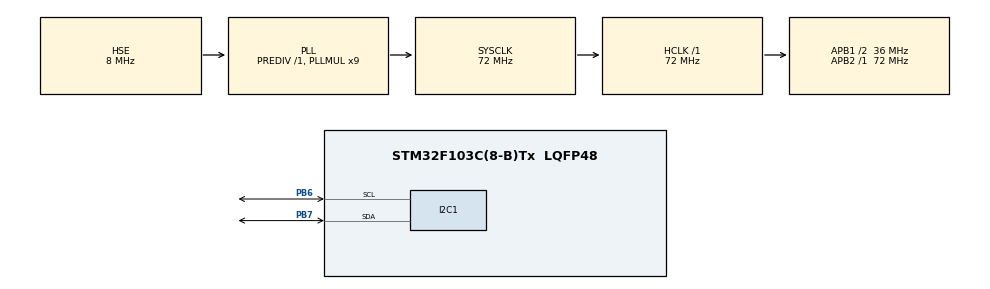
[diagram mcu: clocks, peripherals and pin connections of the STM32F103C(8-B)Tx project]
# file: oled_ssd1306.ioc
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I2C1.I2C_Mode=I2C_Fast
Mcu.Family=STM32F1
Mcu.Name=STM32F103C(8-B)Tx
Mcu.Package=LQFP48
NVIC.PriorityGroup=NVIC_PRIORITYGROUP_4
PA13.Mode=Serial_Wire
PA13.Signal=SYS_JTMS-SWDIO
PA14.Mode=Serial_Wire
PA14.Signal=SYS_JTCK-SWCLK
PB6.Mode=I2C
PB6.Signal=I2C1_SCL
PB7.Mode=I2C
PB7.Signal=I2C1_SDA
PD0-OSC_IN.Mode=HSE-External-Oscillator
PD0-OSC_IN.Signal=RCC_OSC_IN
PD1-OSC_OUT.Mode=HSE-External-Oscillator
PD1-OSC_OUT.Signal=RCC_OSC_OUT
ProjectManager.HeapSize=0x200
ProjectManager.StackSize=0x400
ProjectManager.TargetToolchain=STM32CubeIDE
RCC.AHBFreq_Value=72000000
RCC.APB1CLKDivider=RCC_HCLK_DIV2
RCC.APB1Freq_Value=36000000
RCC.APB1TimFreq_Value=72000000
RCC.APB2Freq_Value=72000000
RCC.APB2TimFreq_Value=72000000
RCC.HCLKFreq_Value=72000000
RCC.PLLMUL=RCC_PLL_MUL9
RCC.PLLSourceVirtual=RCC_PLLSOURCE_HSE
RCC.SYSCLKFreq_VALUE=72000000
RCC.SYSCLKSource=RCC_SYSCLKSOURCE_PLLCLK
RCC.USBFreq_Value=72000000
board=custom

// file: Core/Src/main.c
/* USER CODE BEGIN Header */
/**
  ******************************************************************************
  * @file           : main.c
  * @brief          : Main program body
  ******************************************************************************
  * @attention
  *
  * <h2><center>&copy; Copyright (c) 2021 STMicroelectronics.
  * All rights reserved.</center></h2>
  *
  * This software component is licensed by ST under BSD 3-Clause license,
  * the "License"; You may not use this file except in compliance with the
  * License. You may obtain a copy of the License at:
  *                        opensource.org/licenses/BSD-3-Clause
  *
  ******************************************************************************
  */
/* USER CODE END Header */
#include "main.h"
/* USER CODE BEGIN Includes */
#include "fonts.h"
#include "ssd1306.h"
#include "test.h"
#include "bitmap.h"
/* USER CODE END Includes */

I2C_HandleTypeDef hi2c1;

void SystemClock_Config(void);
static void MX_GPIO_Init(void);
static void MX_I2C1_Init(void);

/* USER CODE BEGIN 0 */

// FUNCION UTIL PARA CONTAR LA CANTIDAD DE DIGITOS DE UN NUMERO
int count_digits(int number)
{
	int digits = 0;
	while(number)
	{
		number /= 10;
		digits++;
	}
	return digits;
}

// IMPRIME EL ICONO DE BATERIA (VALORES DE 0 A 4, 4=LLENA, 0=VACIA)
void printoled_battery(int state)
{
	SSD1306_DrawBitmap(95, 0, battery_icon_4, 32, 18, 0); //LIMPIO LA ZONA
	SSD1306_UpdateScreen();
	switch(state){
	case 0:
		SSD1306_DrawBitmap(95, 0, battery_icon_0, 32, 18, 1); //ORIGINAL
		break;
	case 1:
		SSD1306_DrawBitmap(95, 0, battery_icon_1, 32, 18, 1); //ORIGINAL
		break;
	case 2:
		SSD1306_DrawBitmap(95, 0, battery_icon_2, 32, 18, 1); //ORIGINAL
		break;
	case 3:
		SSD1306_DrawBitmap(95, 0, battery_icon_3, 32, 18, 1); //ORIGINAL
		break;
	case 4:
		SSD1306_DrawBitmap(95, 0, battery_icon_4, 32, 18, 1); //ORIGINAL
		break;
	default:
		state = 0;
	}
	SSD1306_UpdateScreen();
}

// IMPRIME EL MENU
void printoled_menu()
{
	SSD1306_GotoXY(0,0);
	SSD1306_Puts("MENU", &Font_7x10, 1);
	SSD1306_GotoXY(0,10);
	SSD1306_Puts("1- Pesar", &Font_7x10, 1);
	SSD1306_GotoXY(0,20);
	SSD1306_Puts("2- Calibrar", &Font_7x10, 1);
	SSD1306_GotoXY(0,30);
	SSD1306_Puts("3- Tarar", &Font_7x10, 1);
	SSD1306_GotoXY(0,40);
	SSD1306_Puts("4- Calcular Precio", &Font_7x10, 1);
	SSD1306_GotoXY(0,50);
	SSD1306_Puts("5- Conectar a PC", &Font_7x10, 1);
	SSD1306_UpdateScreen();
}

//RECIBE UN VALOR INT DE PESO(EN GRAMOS) Y LO IMPRIME EN PANTALLA INCLUYENDO 'g' SI UNIT=0 o 'kg' SI UNIT=1 Y WEIGHT ES MAYOR A 1000
//EN CASO DE UNIT=1 SOLO IMRPIME NUMEROS DE HASTA 9,999 KG (PARA ESTA BALANZA ES SUFICIENTE)
void printoled_weight(int weight,int unit)
{
	int i,w,digits;
	int div = 1;
	digits = count_digits(weight);
	if(weight < 1000)
		unit = 0;
	char weight_shown[digits+1+unit];

	if(digits > 1){
		for(i=1 ; i<digits ; i++)
			div*=10;
	}
	for(i=0 ; i<digits+unit ; i++){
		if( unit==1 && i==1 )
			weight_shown[i] = ',';
		else{
		w = (weight/div);
		weight_shown[i] = w + '0';
		weight -= w*div;
		div /= 10;
		}
	}
	weight_shown[i] = '\0';

	SSD1306_GotoXY(60-8*digits-20*unit,20);
	SSD1306_Puts(weight_shown, &Font_16x26, 1);
	if(unit){
		SSD1306_GotoXY(95,20);
		SSD1306_Puts("Kg", &Font_16x26, 1);
	}
	else{
		SSD1306_GotoXY(65+8*digits,20);
		SSD1306_Puts("g", &Font_16x26, 1);
	}
	SSD1306_UpdateScreen();
}

// IMPRIMIR EL TEXTO DE INICIO DE LA BALANZA
void printoled_start()
{
	 SSD1306_GotoXY(10,10);
	 SSD1306_Puts(" BALANZA",&Font_11x18,1);
	 SSD1306_GotoXY(10,30);
	 SSD1306_Puts(" DIGITAL", &Font_11x18, 1);
	 SSD1306_UpdateScreen();
}

//RECIBE UN VALOR ENTRE 0 Y 9 Y LO IMPRIME, AGREGANDO EL VALOR RECIBIDO AL ANTERIOR PARA FORMAR NUMEROS DE VARIOS DIGITOS (HASTA 5) A PARTIR DE CADA DIGITO
//SI RECIBE -1 ELIMINA TODA LA COLA DE NUMEROS Y BORRA LA PANTALLA
void printoled_number(int number)
{
	static int i=0;
	static char number_shown[6];
	number_shown[i] = number + '0';
	number_shown[i+1] = '\0';
	if(number >= 0){
		SSD1306_GotoXY(55-6*i,20);
		SSD1306_Puts(number_shown, &Font_16x26, 1);
		SSD1306_UpdateScreen();
		i++;
	}
	else{
		i=0;
		number_shown[0] = '\0';;
		SSD1306_Clear();
	}
}

//RECIBE UN VALOR DE PRECIO E IMPIRME INCLUYENDO EL $
void printoled_price(int price)
{
	int i,p,digits;
	int div = 1;
	digits = count_digits(price);
	char price_shown[digits+1];

	if(digits > 1){
			for(i=1 ; i<digits ; i++)
				div*=10;
	}
	/* ESTA VERSION ES CON EL SIGNO PESOS MAS CHICO PERO SE VE MEJOR*/
	SSD1306_GotoXY(52-8*digits,23);
	SSD1306_Putc('$', &Font_11x18, 1);
	for(i=0 ; i<digits ; i++)
	{
			p = (price/div);
			price_shown[i] = p + '0';
			price -= p*div;
			div /= 10;
	}
	price_shown[i] = '\0';

	SSD1306_GotoXY(65-8*digits,20);
	SSD1306_Puts(price_shown, &Font_16x26, 1);
	/**/
	/*//ESTA VERSION ES CON EL SIGNO PESOS GRANDE PERO SE VE FEO
	price_shown[0] = '$';
	for(i=1 ; i<=digits ; i++)
	{
			p = (price/div);
			price_shown[i] = p + '0';
			price -= p*div;
			div /= 10;
	}
	price_shown[i] = '\0';

	SSD1306_GotoXY(60-8*digits,20);
	SSD1306_Puts(price_shown, &Font_16x26, 1);
	*/

	SSD1306_UpdateScreen();
}

/* USER CODE END 0 */

int main(void)
{

  /* MCU Configuration--------------------------------------------------------*/

  /* Reset of all peripherals, Initializes the Flash interface and the Systick. */
  HAL_Init();

  /* Configure the system clock */
  SystemClock_Config();

  /* Initialize all configured peripherals */
  MX_GPIO_Init();
  MX_I2C1_Init();
  /* USER CODE BEGIN 2 */
  SSD1306_Init(); //INICIALIZACION

/*  SSD1306_ScrollRight(0x00, 0x0F);
  HAL_Delay(2000);
  SSD1306_ScrollLeft(0x00, 0x0F);
  HAL_Delay(2000);
  SSD1306_Stopscroll();*/
  /* USER CODE END 2 */

  /* Infinite loop */
  while (1)
  {
    /* USER CODE BEGIN 3 */
	  	printoled_start();
	  	HAL_Delay(2000);
		SSD1306_Clear();

	  	printoled_menu();
	  	printoled_battery(4);
	  	HAL_Delay(2000);
	  	printoled_battery(3);
	   	HAL_Delay(2000);
	  	printoled_battery(2);
	   	HAL_Delay(2000);
	  	printoled_battery(1);
	   	HAL_Delay(2000);
	  	printoled_battery(0);
	   	HAL_Delay(2000);
	   	SSD1306_Clear();

	    printoled_weight(3,0);
	    HAL_Delay(2000);
	    SSD1306_Clear();

	    printoled_weight(56,0);
	    HAL_Delay(2000);
	    SSD1306_Clear();

	    printoled_weight(892,1);
	    HAL_Delay(2000);
	    SSD1306_Clear();

	    printoled_weight(2394,0);
	    HAL_Delay(2000);
	    SSD1306_Clear();

	    printoled_weight(9999,1);
	    HAL_Delay(2000);
	    SSD1306_Clear();

	    //recibo e imprimo acumulando
	    printoled_number(1);
	    HAL_Delay(1000);
	    printoled_number(5);
	    HAL_Delay(1000);
	    printoled_number(0);
	    HAL_Delay(2000);
	    printoled_number(-1); //para terminar la tira de valores

	    printoled_price(2);
	    HAL_Delay(2000);
	    SSD1306_Clear();
	    printoled_price(32);
	    HAL_Delay(2000);
	    SSD1306_Clear();
	    printoled_price(470);
	    HAL_Delay(2000);
	    SSD1306_Clear();
	    printoled_price(8202);
	    HAL_Delay(2000);
	    SSD1306_Clear();

  }
  /* USER CODE END 3 */
}

void SystemClock_Config(void)
{
  RCC_OscInitTypeDef RCC_OscInitStruct = {0};
  RCC_ClkInitTypeDef RCC_ClkInitStruct = {0};

  /** Initializes the RCC Oscillators according to the specified parameters
  * in the RCC_OscInitTypeDef structure.
  */
  RCC_OscInitStruct.OscillatorType = RCC_OSCILLATORTYPE_HSE;
  RCC_OscInitStruct.HSEState = RCC_HSE_ON;
  RCC_OscInitStruct.HSEPredivValue = RCC_HSE_PREDIV_DIV1;
  RCC_OscInitStruct.HSIState = RCC_HSI_ON;
  RCC_OscInitStruct.PLL.PLLState = RCC_PLL_ON;
  RCC_OscInitStruct.PLL.PLLSource = RCC_PLLSOURCE_HSE;
  RCC_OscInitStruct.PLL.PLLMUL = RCC_PLL_MUL9;
  if (HAL_RCC_OscConfig(&RCC_OscInitStruct) != HAL_OK)
  {
    Error_Handler();
  }
  /** Initializes the CPU, AHB and APB buses clocks
  */
  RCC_ClkInitStruct.ClockType = RCC_CLOCKTYPE_HCLK|RCC_CLOCKTYPE_SYSCLK
                              |RCC_CLOCKTYPE_PCLK1|RCC_CLOCKTYPE_PCLK2;
  RCC_ClkInitStruct.SYSCLKSource = RCC_SYSCLKSOURCE_PLLCLK;
  RCC_ClkInitStruct.AHBCLKDivider = RCC_SYSCLK_DIV1;
  RCC_ClkInitStruct.APB1CLKDivider = RCC_HCLK_DIV2;
  RCC_ClkInitStruct.APB2CLKDivider = RCC_HCLK_DIV1;

  if (HAL_RCC_ClockConfig(&RCC_ClkInitStruct, FLASH_LATENCY_2) != HAL_OK)
  {
    Error_Handler();
  }
}

static void MX_I2C1_Init(void)
{

  hi2c1.Instance = I2C1;
  hi2c1.Init.ClockSpeed = 400000;
  hi2c1.Init.DutyCycle = I2C_DUTYCYCLE_2;
  hi2c1.Init.OwnAddress1 = 0;
  hi2c1.Init.AddressingMode = I2C_ADDRESSINGMODE_7BIT;
  hi2c1.Init.DualAddressMode = I2C_DUALADDRESS_DISABLE;
  hi2c1.Init.OwnAddress2 = 0;
  hi2c1.Init.GeneralCallMode = I2C_GENERALCALL_DISABLE;
  hi2c1.Init.NoStretchMode = I2C_NOSTRETCH_DISABLE;
  if (HAL_I2C_Init(&hi2c1) != HAL_OK)
  {
    Error_Handler();
  }

}

static void MX_GPIO_Init(void)
{

  /* GPIO Ports Clock Enable */
  __HAL_RCC_GPIOD_CLK_ENABLE();
  __HAL_RCC_GPIOA_CLK_ENABLE();
  __HAL_RCC_GPIOB_CLK_ENABLE();

}

void Error_Handler(void)
{
  __disable_irq();
  while (1)
  {
  }
}

/************************ (C) COPYRIGHT STMicroelectronics *****END OF FILE****/
